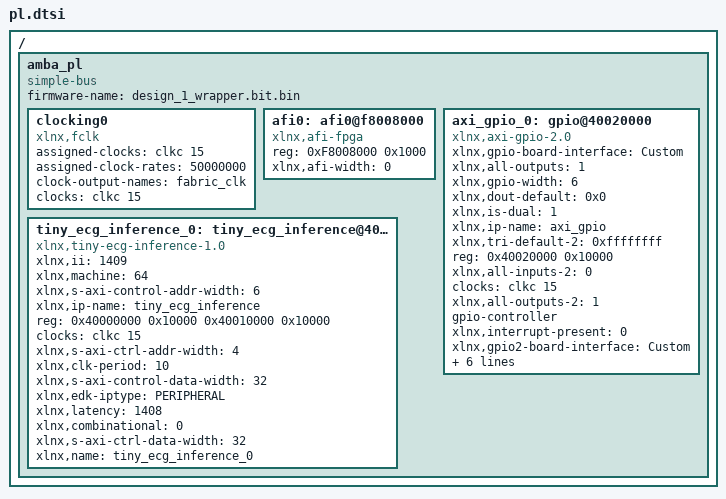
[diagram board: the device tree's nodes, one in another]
/ {
	amba_pl: amba_pl {
		ranges;
		compatible = "simple-bus";
		#address-cells = <1>;
		#size-cells = <1>;
		firmware-name = "design_1_wrapper.bit.bin";
		clocking0: clocking0 {
			compatible = "xlnx,fclk";
			assigned-clocks = <&clkc 15>;
			assigned-clock-rates = <50000000>;
			#clock-cells = <0>;
			clock-output-names = "fabric_clk";
			clocks = <&clkc 15>;
		};
		afi0: afi0@f8008000 {
			status = "okay";
			compatible = "xlnx,afi-fpga";
			#address-cells = <1>;
			reg = <0xF8008000 0x1000>;
			#size-cells = <0>;
			xlnx,afi-width = <0>;
		};
		axi_gpio_0: gpio@40020000 {
			xlnx,gpio-board-interface = "Custom";
			compatible = "xlnx,axi-gpio-2.0" , "xlnx,xps-gpio-1.00.a";
			xlnx,all-outputs = <1>;
			#gpio-cells = <2>;
			xlnx,gpio-width = <6>;
			xlnx,dout-default = <0x0>;
			xlnx,is-dual = <1>;
			xlnx,ip-name = "axi_gpio";
			xlnx,tri-default-2 = <0xffffffff>;
			reg = <0x40020000 0x10000>;
			xlnx,all-inputs-2 = <0>;
			clocks = <&clkc 15>;
			xlnx,all-outputs-2 = <1>;
			gpio-controller;
			device_type = "gpio";
			xlnx,interrupt-present = <0>;
			xlnx,gpio2-board-interface = "Custom";
			xlnx,edk-iptype = "PERIPHERAL";
			xlnx,dout-default-2 = <0x0>;
			status = "okay";
			xlnx,gpio2-width = <1>;
			clock-names = "s_axi_aclk";
			xlnx,tri-default = <0xffffffff>;
			xlnx,name = "axi_gpio_0";
			xlnx,all-inputs = <0>;
		};
		tiny_ecg_inference_0: tiny_ecg_inference@40000000 {
			xlnx,ii = <1409>;
			compatible = "xlnx,tiny-ecg-inference-1.0";
			xlnx,machine = <64>;
			xlnx,s-axi-control-addr-width = <6>;
			xlnx,ip-name = "tiny_ecg_inference";
			reg = <0x40000000 0x10000 0x40010000 0x10000>;
			clocks = <&clkc 15>;
			xlnx,s-axi-ctrl-addr-width = <4>;
			xlnx,clk-period = <10>;
			xlnx,s-axi-control-data-width = <32>;
			xlnx,edk-iptype = "PERIPHERAL";
			status = "okay";
			clock-names = "ap_clk";
			xlnx,latency = <1408>;
			xlnx,combinational = <0>;
			xlnx,s-axi-ctrl-data-width = <32>;
			xlnx,name = "tiny_ecg_inference_0";
		};
	};
};
